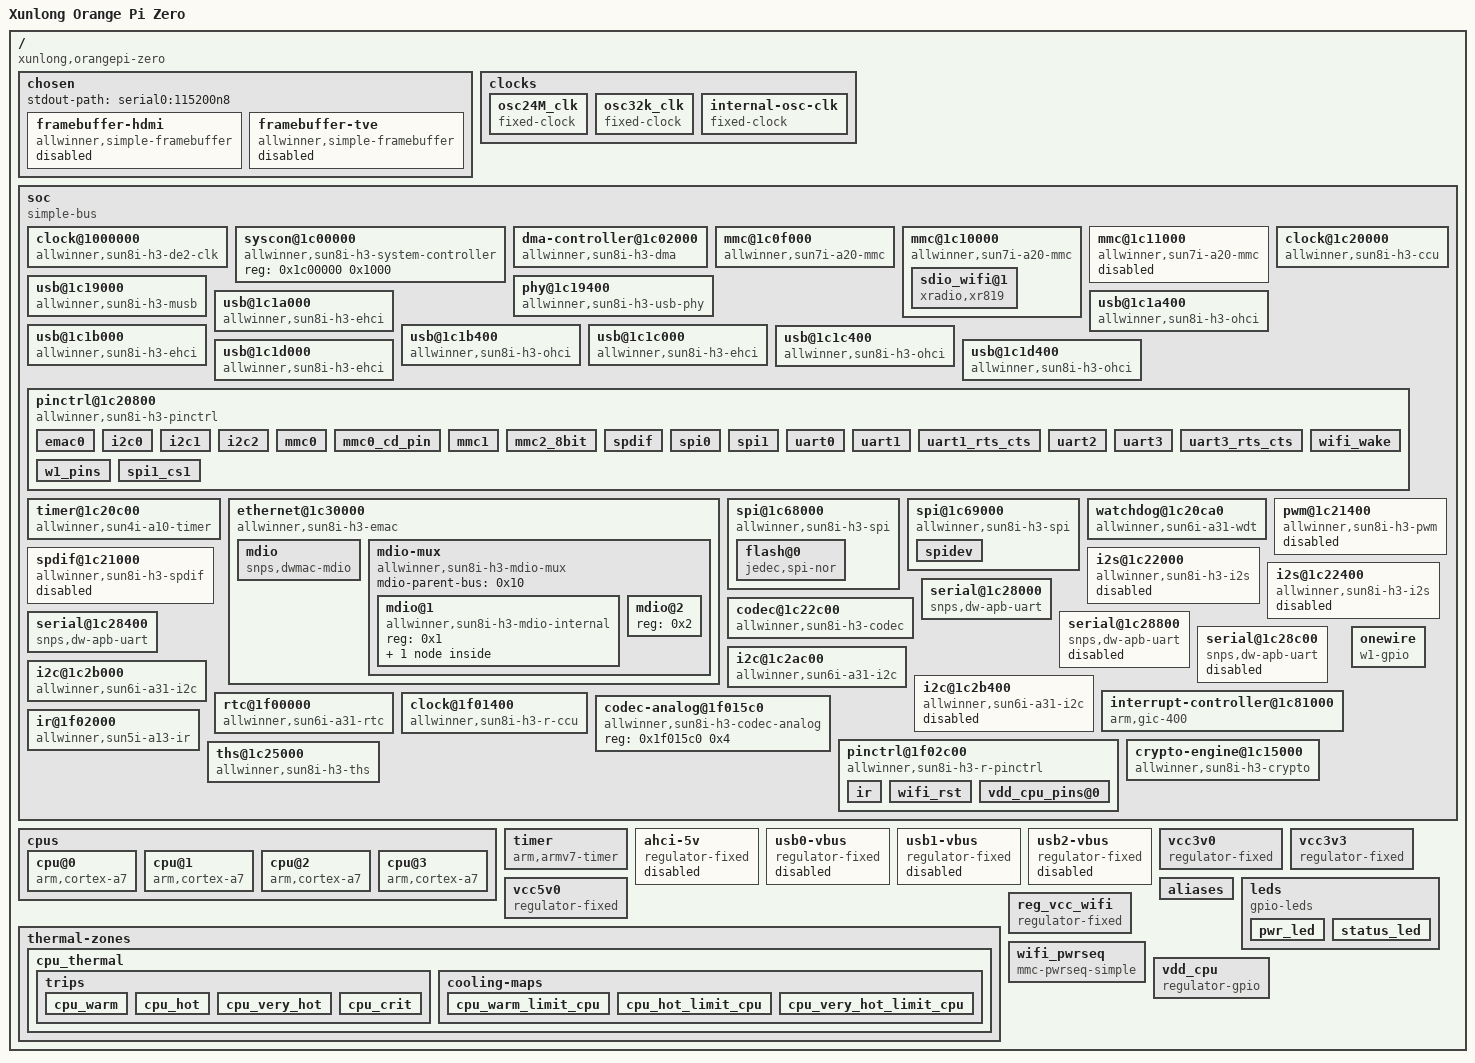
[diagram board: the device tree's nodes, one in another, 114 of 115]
/dts-v1/;

/ {
	interrupt-parent = <0x1>;
	#address-cells = <0x1>;
	#size-cells = <0x1>;
	model = "Xunlong Orange Pi Zero";
	compatible = "xunlong,orangepi-zero", "allwinner,sun8i-h2-plus";

	chosen {
		#address-cells = <0x1>;
		#size-cells = <0x1>;
		ranges;
		stdout-path = "serial0:115200n8";

		framebuffer-hdmi {
			compatible = "allwinner,simple-framebuffer", "simple-framebuffer";
			allwinner,pipeline = "mixer0-lcd0-hdmi";
			clocks = <0x2 0x6 0x3 0x66 0x3 0x6f>;
			status = "disabled";
		};

		framebuffer-tve {
			compatible = "allwinner,simple-framebuffer", "simple-framebuffer";
			allwinner,pipeline = "mixer1-lcd1-tve";
			clocks = <0x2 0x7 0x3 0x67>;
			status = "disabled";
		};
	};

	clocks {
		#address-cells = <0x1>;
		#size-cells = <0x1>;
		ranges;

		osc24M_clk {
			#clock-cells = <0x0>;
			compatible = "fixed-clock";
			clock-frequency = <0x16e3600>;
			clock-output-names = "osc24M";
			phandle = <0xc>;
		};

		osc32k_clk {
			#clock-cells = <0x0>;
			compatible = "fixed-clock";
			clock-frequency = <0x8000>;
			clock-output-names = "osc32k";
			phandle = <0xd>;
		};

		internal-osc-clk {
			#clock-cells = <0x0>;
			compatible = "fixed-clock";
			clock-frequency = <0xf42400>;
			clock-accuracy = <0x11e1a300>;
			clock-output-names = "iosc";
			phandle = <0x1c>;
		};
	};

	soc {
		compatible = "simple-bus";
		#address-cells = <0x1>;
		#size-cells = <0x1>;
		ranges;

		clock@1000000 {
			reg = <0x1000000 0x100000>;
			clocks = <0x3 0x65 0x3 0x30>;
			clock-names = "mod", "bus";
			resets = <0x3 0x22>;
			#clock-cells = <0x1>;
			#reset-cells = <0x1>;
			compatible = "allwinner,sun8i-h3-de2-clk";
			phandle = <0x2>;
		};

		syscon@1c00000 {
			compatible = "allwinner,sun8i-h3-system-controller", "syscon";
			reg = <0x1c00000 0x1000>;
			phandle = <0xe>;
		};

		dma-controller@1c02000 {
			compatible = "allwinner,sun8i-h3-dma";
			reg = <0x1c02000 0x1000>;
			interrupts = <0x0 0x32 0x4>;
			clocks = <0x3 0x15>;
			resets = <0x3 0x6>;
			#dma-cells = <0x1>;
			phandle = <0x11>;
		};

		mmc@1c0f000 {
			reg = <0x1c0f000 0x1000>;
			resets = <0x3 0x7>;
			reset-names = "ahb";
			interrupts = <0x0 0x3c 0x4>;
			status = "okay";
			#address-cells = <0x1>;
			#size-cells = <0x0>;
			compatible = "allwinner,sun7i-a20-mmc";
			clocks = <0x3 0x16 0x3 0x47 0x3 0x49 0x3 0x48>;
			clock-names = "ahb", "mmc", "output", "sample";
			pinctrl-names = "default";
			pinctrl-0 = <0x4>;
			vmmc-supply = <0x5>;
			bus-width = <0x4>;
			cd-gpios = <0x6 0x5 0x6 0x0>;
			cd-inverted;
		};

		mmc@1c10000 {
			reg = <0x1c10000 0x1000>;
			resets = <0x3 0x8>;
			reset-names = "ahb";
			interrupts = <0x0 0x3d 0x4>;
			status = "okay";
			#address-cells = <0x1>;
			#size-cells = <0x0>;
			compatible = "allwinner,sun7i-a20-mmc";
			clocks = <0x3 0x17 0x3 0x4a 0x3 0x4c 0x3 0x4b>;
			clock-names = "ahb", "mmc", "output", "sample";
			pinctrl-names = "default";
			pinctrl-0 = <0x7>;
			vmmc-supply = <0x5>;
			vqmmc-supply = <0x8>;
			mmc-pwrseq = <0x9>;
			bus-width = <0x4>;
			max-frequency = <0xf42400>;
			non-removable;

			sdio_wifi@1 {
				reg = <0x1>;
				compatible = "xradio,xr819";
				pinctrl-names = "default";
				pinctrl-0 = <0xa>;
				interrupt-parent = <0x6>;
				interrupts = <0x6 0xa 0x1>;
				interrupt-names = "host-wake";
			};
		};

		mmc@1c11000 {
			reg = <0x1c11000 0x1000>;
			resets = <0x3 0x9>;
			reset-names = "ahb";
			interrupts = <0x0 0x3e 0x4>;
			status = "disabled";
			#address-cells = <0x1>;
			#size-cells = <0x0>;
			compatible = "allwinner,sun7i-a20-mmc";
			clocks = <0x3 0x18 0x3 0x4d 0x3 0x4f 0x3 0x4e>;
			clock-names = "ahb", "mmc", "output", "sample";
		};

		usb@1c19000 {
			compatible = "allwinner,sun8i-h3-musb";
			reg = <0x1c19000 0x400>;
			clocks = <0x3 0x20>;
			resets = <0x3 0x11>;
			interrupts = <0x0 0x47 0x4>;
			interrupt-names = "mc";
			phys = <0xb 0x0>;
			phy-names = "usb";
			extcon = <0xb 0x0>;
			status = "okay";
			dr_mode = "peripheral";
		};

		phy@1c19400 {
			compatible = "allwinner,sun8i-h3-usb-phy";
			reg = <0x1c19400 0x2c 0x1c1a800 0x4 0x1c1b800 0x4 0x1c1c800 0x4 0x1c1d800 0x4>;
			reg-names = "phy_ctrl", "pmu0", "pmu1", "pmu2", "pmu3";
			clocks = <0x3 0x58 0x3 0x59 0x3 0x5a 0x3 0x5b>;
			clock-names = "usb0_phy", "usb1_phy", "usb2_phy", "usb3_phy";
			resets = <0x3 0x0 0x3 0x1 0x3 0x2 0x3 0x3>;
			reset-names = "usb0_reset", "usb1_reset", "usb2_reset", "usb3_reset";
			status = "okay";
			#phy-cells = <0x1>;
			usb0_id_det-gpios = <0x6 0x6 0xc 0x0>;
			phandle = <0xb>;
		};

		usb@1c1a000 {
			compatible = "allwinner,sun8i-h3-ehci", "generic-ehci";
			reg = <0x1c1a000 0x100>;
			interrupts = <0x0 0x48 0x4>;
			clocks = <0x3 0x21 0x3 0x25>;
			resets = <0x3 0x12 0x3 0x16>;
			status = "okay";
		};

		usb@1c1a400 {
			compatible = "allwinner,sun8i-h3-ohci", "generic-ohci";
			reg = <0x1c1a400 0x100>;
			interrupts = <0x0 0x49 0x4>;
			clocks = <0x3 0x21 0x3 0x25 0x3 0x5c>;
			resets = <0x3 0x12 0x3 0x16>;
			status = "okay";
		};

		usb@1c1b000 {
			compatible = "allwinner,sun8i-h3-ehci", "generic-ehci";
			reg = <0x1c1b000 0x100>;
			interrupts = <0x0 0x4a 0x4>;
			clocks = <0x3 0x22 0x3 0x26>;
			resets = <0x3 0x13 0x3 0x17>;
			phys = <0xb 0x1>;
			phy-names = "usb";
			status = "okay";
		};

		usb@1c1b400 {
			compatible = "allwinner,sun8i-h3-ohci", "generic-ohci";
			reg = <0x1c1b400 0x100>;
			interrupts = <0x0 0x4b 0x4>;
			clocks = <0x3 0x22 0x3 0x26 0x3 0x5d>;
			resets = <0x3 0x13 0x3 0x17>;
			phys = <0xb 0x1>;
			phy-names = "usb";
			status = "okay";
		};

		usb@1c1c000 {
			compatible = "allwinner,sun8i-h3-ehci", "generic-ehci";
			reg = <0x1c1c000 0x100>;
			interrupts = <0x0 0x4c 0x4>;
			clocks = <0x3 0x23 0x3 0x27>;
			resets = <0x3 0x14 0x3 0x18>;
			phys = <0xb 0x2>;
			phy-names = "usb";
			status = "okay";
		};

		usb@1c1c400 {
			compatible = "allwinner,sun8i-h3-ohci", "generic-ohci";
			reg = <0x1c1c400 0x100>;
			interrupts = <0x0 0x4d 0x4>;
			clocks = <0x3 0x23 0x3 0x27 0x3 0x5e>;
			resets = <0x3 0x14 0x3 0x18>;
			phys = <0xb 0x2>;
			phy-names = "usb";
			status = "okay";
		};

		usb@1c1d000 {
			compatible = "allwinner,sun8i-h3-ehci", "generic-ehci";
			reg = <0x1c1d000 0x100>;
			interrupts = <0x0 0x4e 0x4>;
			clocks = <0x3 0x24 0x3 0x28>;
			resets = <0x3 0x15 0x3 0x19>;
			phys = <0xb 0x3>;
			phy-names = "usb";
			status = "okay";
		};

		usb@1c1d400 {
			compatible = "allwinner,sun8i-h3-ohci", "generic-ohci";
			reg = <0x1c1d400 0x100>;
			interrupts = <0x0 0x4f 0x4>;
			clocks = <0x3 0x24 0x3 0x28 0x3 0x5f>;
			resets = <0x3 0x15 0x3 0x19>;
			phys = <0xb 0x3>;
			phy-names = "usb";
			status = "okay";
		};

		clock@1c20000 {
			reg = <0x1c20000 0x400>;
			clocks = <0xc 0xd>;
			clock-names = "hosc", "losc";
			#clock-cells = <0x1>;
			#reset-cells = <0x1>;
			compatible = "allwinner,sun8i-h3-ccu";
			phandle = <0x3>;
		};

		pinctrl@1c20800 {
			reg = <0x1c20800 0x400>;
			interrupts = <0x0 0xb 0x4 0x0 0x11 0x4>;
			clocks = <0x3 0x36 0xc 0xd>;
			clock-names = "apb", "hosc", "losc";
			gpio-controller;
			#gpio-cells = <0x3>;
			interrupt-controller;
			#interrupt-cells = <0x3>;
			compatible = "allwinner,sun8i-h3-pinctrl";
			phandle = <0x6>;

			emac0 {
				pins = "PD0", "PD1", "PD2", "PD3", "PD4", "PD5", "PD7", "PD8", "PD9", "PD10", "PD12", "PD13", "PD15", "PD16", "PD17";
				function = "emac";
				drive-strength = <0x28>;
			};

			i2c0 {
				pins = "PA11", "PA12";
				function = "i2c0";
				phandle = <0x19>;
			};

			i2c1 {
				pins = "PA18", "PA19";
				function = "i2c1";
				phandle = <0x1a>;
			};

			i2c2 {
				pins = "PE12", "PE13";
				function = "i2c2";
				phandle = <0x1b>;
			};

			mmc0 {
				pins = "PF0", "PF1", "PF2", "PF3", "PF4", "PF5";
				function = "mmc0";
				drive-strength = <0x1e>;
				bias-pull-up;
				phandle = <0x4>;
			};

			mmc0_cd_pin {
				pins = "PF6";
				function = "gpio_in";
				bias-pull-up;
			};

			mmc1 {
				pins = "PG0", "PG1", "PG2", "PG3", "PG4", "PG5";
				function = "mmc1";
				drive-strength = <0x1e>;
				bias-pull-up;
				phandle = <0x7>;
			};

			mmc2_8bit {
				pins = "PC5", "PC6", "PC8", "PC9", "PC10", "PC11", "PC12", "PC13", "PC14", "PC15", "PC16";
				function = "mmc2";
				drive-strength = <0x1e>;
				bias-pull-up;
			};

			spdif {
				pins = "PA17";
				function = "spdif";
			};

			spi0 {
				pins = "PC0", "PC1", "PC2", "PC3";
				function = "spi0";
				phandle = <0x12>;
			};

			spi1 {
				pins = "PA15", "PA16", "PA14", "PA13";
				function = "spi1";
				phandle = <0x13>;
			};

			uart0 {
				pins = "PA4", "PA5";
				function = "uart0";
				phandle = <0x16>;
			};

			uart1 {
				pins = "PG6", "PG7";
				function = "uart1";
				phandle = <0x17>;
			};

			uart1_rts_cts {
				pins = "PG8", "PG9";
				function = "uart1";
			};

			uart2 {
				pins = "PA0", "PA1";
				function = "uart2";
				phandle = <0x18>;
			};

			uart3 {
				pins = "PA13", "PA14";
				function = "uart3";
			};

			uart3_rts_cts {
				pins = "PA15", "PA16";
				function = "uart3";
			};

			wifi_wake {
				pins = "PG10";
				function = "gpio_in";
				phandle = <0xa>;
			};

			w1_pins {
				pins = "PA02";
				function = "gpio_in";
				bias-pull-up;
				phandle = <0x1f>;
			};

			spi1_cs1 {
				pins = "PA13";
				function = "gpio_out";
				output-high;
				phandle = <0x14>;
			};
		};

		timer@1c20c00 {
			compatible = "allwinner,sun4i-a10-timer";
			reg = <0x1c20c00 0xa0>;
			interrupts = <0x0 0x12 0x4 0x0 0x13 0x4>;
			clocks = <0xc>;
		};

		ethernet@1c30000 {
			compatible = "allwinner,sun8i-h3-emac";
			syscon = <0xe>;
			reg = <0x1c30000 0x10000>;
			interrupts = <0x0 0x52 0x4>;
			interrupt-names = "macirq";
			resets = <0x3 0xc>;
			reset-names = "stmmaceth";
			clocks = <0x3 0x1b>;
			clock-names = "stmmaceth";
			#address-cells = <0x1>;
			#size-cells = <0x0>;
			status = "okay";
			phy-handle = <0xf>;
			phy-mode = "mii";
			allwinner,leds-active-low;

			mdio {
				#address-cells = <0x1>;
				#size-cells = <0x0>;
				compatible = "snps,dwmac-mdio";
				phandle = <0x10>;
			};

			mdio-mux {
				compatible = "allwinner,sun8i-h3-mdio-mux";
				#address-cells = <0x1>;
				#size-cells = <0x0>;
				mdio-parent-bus = <0x10>;

				mdio@1 {
					compatible = "allwinner,sun8i-h3-mdio-internal";
					reg = <0x1>;
					#address-cells = <0x1>;
					#size-cells = <0x0>;

					ethernet-phy@1 {
						compatible = "ethernet-phy-ieee802.3-c22";
						reg = <0x1>;
						clocks = <0x3 0x43>;
						resets = <0x3 0x27>;
						phandle = <0xf>;
					};
				};

				mdio@2 {
					reg = <0x2>;
					#address-cells = <0x1>;
					#size-cells = <0x0>;
				};
			};
		};

		spi@1c68000 {
			compatible = "allwinner,sun8i-h3-spi";
			reg = <0x1c68000 0x1000>;
			interrupts = <0x0 0x41 0x4>;
			clocks = <0x3 0x1e 0x3 0x52>;
			clock-names = "ahb", "mod";
			dmas = <0x11 0x17 0x11 0x17>;
			dma-names = "rx", "tx";
			pinctrl-names = "default";
			pinctrl-0 = <0x12>;
			resets = <0x3 0xf>;
			status = "okay";
			#address-cells = <0x1>;
			#size-cells = <0x0>;

			flash@0 {
				#address-cells = <0x1>;
				#size-cells = <0x1>;
				compatible = "jedec,spi-nor";
				reg = <0x0>;
				spi-max-frequency = <0xf4240>;
				status = "okay";
			};
		};

		spi@1c69000 {
			compatible = "allwinner,sun8i-h3-spi";
			reg = <0x1c69000 0x1000>;
			interrupts = <0x0 0x42 0x4>;
			clocks = <0x3 0x1f 0x3 0x53>;
			clock-names = "ahb", "mod";
			dmas = <0x11 0x18 0x11 0x18>;
			dma-names = "rx", "tx";
			pinctrl-names = "default", "default";
			pinctrl-0 = <0x13>;
			resets = <0x3 0x10>;
			status = "okay";
			#address-cells = <0x1>;
			#size-cells = <0x0>;
			pinctrl-1 = <0x14>;
			cs-gpios = <0x0 0x6 0x0 0xd 0x0>;

			spidev {
				comptabile = "rohm,dh2228fv";
				status = "okay";
				reg = <0x0>;
				spi-max-frequency = <0xf4240>;
			};
		};

		watchdog@1c20ca0 {
			compatible = "allwinner,sun6i-a31-wdt";
			reg = <0x1c20ca0 0x20>;
			interrupts = <0x0 0x19 0x4>;
		};

		spdif@1c21000 {
			#sound-dai-cells = <0x0>;
			compatible = "allwinner,sun8i-h3-spdif";
			reg = <0x1c21000 0x400>;
			interrupts = <0x0 0xc 0x4>;
			clocks = <0x3 0x35 0x3 0x57>;
			resets = <0x3 0x29>;
			clock-names = "apb", "spdif";
			dmas = <0x11 0x2>;
			dma-names = "tx";
			status = "disabled";
		};

		pwm@1c21400 {
			compatible = "allwinner,sun8i-h3-pwm";
			reg = <0x1c21400 0x8>;
			clocks = <0xc>;
			#pwm-cells = <0x3>;
			status = "disabled";
		};

		i2s@1c22000 {
			#sound-dai-cells = <0x0>;
			compatible = "allwinner,sun8i-h3-i2s";
			reg = <0x1c22000 0x400>;
			interrupts = <0x0 0xd 0x4>;
			clocks = <0x3 0x38 0x3 0x54>;
			clock-names = "apb", "mod";
			dmas = <0x11 0x3 0x11 0x3>;
			resets = <0x3 0x2b>;
			dma-names = "rx", "tx";
			status = "disabled";
		};

		i2s@1c22400 {
			#sound-dai-cells = <0x0>;
			compatible = "allwinner,sun8i-h3-i2s";
			reg = <0x1c22400 0x400>;
			interrupts = <0x0 0xe 0x4>;
			clocks = <0x3 0x39 0x3 0x55>;
			clock-names = "apb", "mod";
			dmas = <0x11 0x4 0x11 0x4>;
			resets = <0x3 0x2c>;
			dma-names = "rx", "tx";
			status = "disabled";
		};

		codec@1c22c00 {
			#sound-dai-cells = <0x0>;
			compatible = "allwinner,sun8i-h3-codec";
			reg = <0x1c22c00 0x400>;
			interrupts = <0x0 0x1d 0x4>;
			clocks = <0x3 0x34 0x3 0x6d>;
			clock-names = "apb", "codec";
			resets = <0x3 0x28>;
			dmas = <0x11 0xf 0x11 0xf>;
			dma-names = "rx", "tx";
			allwinner,codec-analog-controls = <0x15>;
			status = "okay";
			allwinner,audio-routing = "Line Out", "LINEOUT", "MIC1", "Mic", "Mic", "MBIAS";
		};

		serial@1c28000 {
			compatible = "snps,dw-apb-uart";
			reg = <0x1c28000 0x400>;
			interrupts = <0x0 0x0 0x4>;
			reg-shift = <0x2>;
			reg-io-width = <0x4>;
			clocks = <0x3 0x3e>;
			resets = <0x3 0x31>;
			dmas = <0x11 0x6 0x11 0x6>;
			dma-names = "rx", "tx";
			status = "okay";
			pinctrl-names = "default";
			pinctrl-0 = <0x16>;
		};

		serial@1c28400 {
			compatible = "snps,dw-apb-uart";
			reg = <0x1c28400 0x400>;
			interrupts = <0x0 0x1 0x4>;
			reg-shift = <0x2>;
			reg-io-width = <0x4>;
			clocks = <0x3 0x3f>;
			resets = <0x3 0x32>;
			dmas = <0x11 0x7 0x11 0x7>;
			dma-names = "rx", "tx";
			status = "okay";
			pinctrl-names = "default";
			pinctrl-0 = <0x17>;
		};

		serial@1c28800 {
			compatible = "snps,dw-apb-uart";
			reg = <0x1c28800 0x400>;
			interrupts = <0x0 0x2 0x4>;
			reg-shift = <0x2>;
			reg-io-width = <0x4>;
			clocks = <0x3 0x40>;
			resets = <0x3 0x33>;
			dmas = <0x11 0x8 0x11 0x8>;
			dma-names = "rx", "tx";
			status = "disabled";
			pinctrl-names = "default";
			pinctrl-0 = <0x18>;
		};

		serial@1c28c00 {
			compatible = "snps,dw-apb-uart";
			reg = <0x1c28c00 0x400>;
			interrupts = <0x0 0x3 0x4>;
			reg-shift = <0x2>;
			reg-io-width = <0x4>;
			clocks = <0x3 0x41>;
			resets = <0x3 0x34>;
			dmas = <0x11 0x9 0x11 0x9>;
			dma-names = "rx", "tx";
			status = "disabled";
		};

		i2c@1c2ac00 {
			compatible = "allwinner,sun6i-a31-i2c";
			reg = <0x1c2ac00 0x400>;
			interrupts = <0x0 0x6 0x4>;
			clocks = <0x3 0x3b>;
			resets = <0x3 0x2e>;
			pinctrl-names = "default";
			pinctrl-0 = <0x19>;
			status = "okay";
			#address-cells = <0x1>;
			#size-cells = <0x0>;
		};

		i2c@1c2b000 {
			compatible = "allwinner,sun6i-a31-i2c";
			reg = <0x1c2b000 0x400>;
			interrupts = <0x0 0x7 0x4>;
			clocks = <0x3 0x3c>;
			resets = <0x3 0x2f>;
			pinctrl-names = "default";
			pinctrl-0 = <0x1a>;
			status = "okay";
			#address-cells = <0x1>;
			#size-cells = <0x0>;
		};

		i2c@1c2b400 {
			compatible = "allwinner,sun6i-a31-i2c";
			reg = <0x1c2b400 0x400>;
			interrupts = <0x0 0x8 0x4>;
			clocks = <0x3 0x3d>;
			resets = <0x3 0x30>;
			pinctrl-names = "default";
			pinctrl-0 = <0x1b>;
			status = "disabled";
			#address-cells = <0x1>;
			#size-cells = <0x0>;
		};

		interrupt-controller@1c81000 {
			compatible = "arm,gic-400";
			reg = <0x1c81000 0x1000 0x1c82000 0x2000 0x1c84000 0x2000 0x1c86000 0x2000>;
			interrupt-controller;
			#interrupt-cells = <0x3>;
			interrupts = <0x1 0x9 0xf04>;
			phandle = <0x1>;
		};

		rtc@1f00000 {
			compatible = "allwinner,sun6i-a31-rtc";
			reg = <0x1f00000 0x54>;
			interrupts = <0x0 0x28 0x4 0x0 0x29 0x4>;
		};

		clock@1f01400 {
			compatible = "allwinner,sun8i-h3-r-ccu";
			reg = <0x1f01400 0x100>;
			clocks = <0xc 0xd 0x1c 0x3 0x9>;
			clock-names = "hosc", "losc", "iosc", "pll-periph";
			#clock-cells = <0x1>;
			#reset-cells = <0x1>;
			phandle = <0x1d>;
		};

		codec-analog@1f015c0 {
			compatible = "allwinner,sun8i-h3-codec-analog";
			reg = <0x1f015c0 0x4>;
			phandle = <0x15>;
		};

		ir@1f02000 {
			compatible = "allwinner,sun5i-a13-ir";
			clocks = <0x1d 0x4 0x1d 0xb>;
			clock-names = "apb", "ir";
			resets = <0x1d 0x0>;
			interrupts = <0x0 0x25 0x4>;
			reg = <0x1f02000 0x40>;
			status = "okay";
			pinctrl-names = "default";
			pinctrl-0 = <0x1e>;
		};

		pinctrl@1f02c00 {
			compatible = "allwinner,sun8i-h3-r-pinctrl";
			reg = <0x1f02c00 0x400>;
			interrupts = <0x0 0x2d 0x4>;
			clocks = <0x1d 0x3 0xc 0xd>;
			clock-names = "apb", "hosc", "losc";
			gpio-controller;
			#gpio-cells = <0x3>;
			interrupt-controller;
			#interrupt-cells = <0x3>;
			phandle = <0x26>;

			ir {
				pins = "PL11";
				function = "s_cir_rx";
				phandle = <0x1e>;
			};

			wifi_rst {
				pins = "PL7";
				function = "gpio_out";
			};

			vdd_cpu_pins@0 {
				allwinner,pins = "PL6";
				allwinner,function = "gpio_out";
				allwinner,drive = <0x0>;
				allwinner,pull = <0x0>;
				phandle = <0x27>;
			};
		};

		crypto-engine@1c15000 {
			compatible = "allwinner,sun8i-h3-crypto", "allwinner,sun4i-a10-crypto", "allwinner,sun6i-a31-crypto", "allwinner,sun7i-a20-crypto";
			reg = <0x1c15000 0x1000>;
			interrupts = <0x0 0x56 0x4>;
			clocks = <0x3 0x18 0x3 0x45>;
			clock-names = "ahb", "mod";
			resets = <0x3 0x5>;
			reset-names = "ahb";
		};

		ths@1c25000 {
			compatible = "allwinner,sun8i-h3-ths";
			reg = <0x1c25000 0x400 0x1c14234 0x4>;
			interrupts = <0x0 0x1f 0x4>;
			#thermal-sensor-cells = <0x0>;
			#io-channel-cells = <0x0>;
			clocks = <0x3 0x37 0x3 0x45>;
			clock-names = "bus", "ths";
			resets = <0x3 0x2a>;
			reset-names = "ahb";
			phandle = <0x21>;
		};

		onewire {
			compatible = "w1-gpio";
			pinctrl-names = "default";
			pinctrl-0 = <0x1f>;
			gpios = <0x6 0x0 0x2 0x0>;
			status = "okay";
		};
	};

	cpus {
		#address-cells = <0x1>;
		#size-cells = <0x0>;

		cpu@0 {
			compatible = "arm,cortex-a7";
			device_type = "cpu";
			reg = <0x0>;
			clocks = <0x3 0xe>;
			clock-latency = <0x3b9b0>;
			clock-frequency = <0x47868c00>;
			operating-points = <0xf6180 0x13d620 0xea600 0x13d620 0xc7380 0x10c8e0 0x9e340 0x10c8e0 0x75300 0x10c8e0 0x639c0 0x10c8e0 0x3a980 0x10c8e0 0x1d4c0 0x10c8e0>;
			#cooling-cells = <0x2>;
			cooling-min-level = <0x0>;
			cooling-max-level = <0x8>;
			cpu0-supply = <0x20>;
			phandle = <0x23>;
		};

		cpu@1 {
			compatible = "arm,cortex-a7";
			device_type = "cpu";
			reg = <0x1>;
			clock-frequency = <0x47868c00>;
		};

		cpu@2 {
			compatible = "arm,cortex-a7";
			device_type = "cpu";
			reg = <0x2>;
			clock-frequency = <0x47868c00>;
		};

		cpu@3 {
			compatible = "arm,cortex-a7";
			device_type = "cpu";
			reg = <0x3>;
			clock-frequency = <0x47868c00>;
		};
	};

	timer {
		compatible = "arm,armv7-timer";
		interrupts = <0x1 0xd 0xf08 0x1 0xe 0xf08 0x1 0xb 0xf08 0x1 0xa 0xf08>;
	};

	ahci-5v {
		compatible = "regulator-fixed";
		regulator-name = "ahci-5v";
		regulator-min-microvolt = <0x4c4b40>;
		regulator-max-microvolt = <0x4c4b40>;
		regulator-boot-on;
		enable-active-high;
		gpio = <0x6 0x1 0x8 0x0>;
		status = "disabled";
	};

	usb0-vbus {
		compatible = "regulator-fixed";
		regulator-name = "usb0-vbus";
		regulator-min-microvolt = <0x4c4b40>;
		regulator-max-microvolt = <0x4c4b40>;
		enable-active-high;
		gpio = <0x6 0x1 0x9 0x0>;
		status = "disabled";
	};

	usb1-vbus {
		compatible = "regulator-fixed";
		regulator-name = "usb1-vbus";
		regulator-min-microvolt = <0x4c4b40>;
		regulator-max-microvolt = <0x4c4b40>;
		regulator-boot-on;
		enable-active-high;
		gpio = <0x6 0x7 0x6 0x0>;
		status = "disabled";
	};

	usb2-vbus {
		compatible = "regulator-fixed";
		regulator-name = "usb2-vbus";
		regulator-min-microvolt = <0x4c4b40>;
		regulator-max-microvolt = <0x4c4b40>;
		regulator-boot-on;
		enable-active-high;
		gpio = <0x6 0x7 0x3 0x0>;
		status = "disabled";
	};

	vcc3v0 {
		compatible = "regulator-fixed";
		regulator-name = "vcc3v0";
		regulator-min-microvolt = <0x2dc6c0>;
		regulator-max-microvolt = <0x2dc6c0>;
	};

	vcc3v3 {
		compatible = "regulator-fixed";
		regulator-name = "vcc3v3";
		regulator-min-microvolt = <0x325aa0>;
		regulator-max-microvolt = <0x325aa0>;
		phandle = <0x5>;
	};

	vcc5v0 {
		compatible = "regulator-fixed";
		regulator-name = "vcc5v0";
		regulator-min-microvolt = <0x4c4b40>;
		regulator-max-microvolt = <0x4c4b40>;
	};

	aliases {
		serial0 = "/soc/serial@1c28000";
		ethernet0 = "/soc/ethernet@1c30000";
		ethernet1 = "/soc/mmc@1c10000/sdio_wifi@1";
		spi0 = "/soc/spi@01c68000";
		spi1 = "/soc/spi@01c69000";
		i2c0 = "/soc/i2c@01c2ac00";
		i2c1 = "/soc/i2c@01c2b000";
		cpu0 = "/cpus/cpu@0";
		serial1 = "/soc/serial@1c28400";
	};

	thermal-zones {

		cpu_thermal {
			polling-delay-passive = <0x14a>;
			polling-delay = <0x3e8>;
			thermal-sensors = <0x21 0x0>;

			trips {

				cpu_warm {
					temperature = <0x9c40>;
					hysteresis = <0x7d0>;
					type = "passive";
					phandle = <0x22>;
				};

				cpu_hot {
					temperature = <0xc350>;
					hysteresis = <0x7d0>;
					type = "passive";
					phandle = <0x24>;
				};

				cpu_very_hot {
					temperature = <0xea60>;
					hysteresis = <0x7d0>;
					type = "passive";
					phandle = <0x25>;
				};

				cpu_crit {
					temperature = <0x11170>;
					hysteresis = <0x7d0>;
					type = "critical";
				};
			};

			cooling-maps {

				cpu_warm_limit_cpu {
					trip = <0x22>;
					cooling-device = <0x23 0xffffffff 0x6>;
				};

				cpu_hot_limit_cpu {
					trip = <0x24>;
					cooling-device = <0x23 0x7 0x7>;
				};

				cpu_very_hot_limit_cpu {
					trip = <0x25>;
					cooling-device = <0x23 0x8 0xffffffff>;
				};
			};
		};
	};

	leds {
		compatible = "gpio-leds";

		pwr_led {
			label = "orangepi:green:pwr";
			gpios = <0x26 0x0 0xa 0x0>;
			default-state = "on";
		};

		status_led {
			label = "orangepi:red:status";
			gpios = <0x6 0x0 0x11 0x0>;
		};
	};

	reg_vcc_wifi {
		compatible = "regulator-fixed";
		regulator-min-microvolt = <0x1b7740>;
		regulator-max-microvolt = <0x1b7740>;
		regulator-name = "vcc-wifi";
		enable-active-high;
		gpio = <0x6 0x0 0x14 0x0>;
		startup-delay-us = <0x11170>;
		phandle = <0x8>;
	};

	wifi_pwrseq {
		compatible = "mmc-pwrseq-simple";
		pinctrl-names = "default";
		reset-gpios = <0x26 0x0 0x7 0x1>;
		post-power-on-delay-ms = <0x32>;
		phandle = <0x9>;
	};

	vdd_cpu {
		compatible = "regulator-gpio";
		pinctrl-names = "default";
		pinctrl-0 = <0x27>;
		regulator-name = "cpu-core";
		regulator-min-microvolt = <0x10c8e0>;
		regulator-max-microvolt = <0x13d620>;
		regulator-boot-on;
		regulator-always-on;
		gpios = <0x26 0x0 0x6 0x0>;
		states = <0x13d620 0x1 0x10c8e0 0x0>;
		startup-delay-us = <0x186a0>;
		enable-active-high;
		phandle = <0x20>;
	};
};
